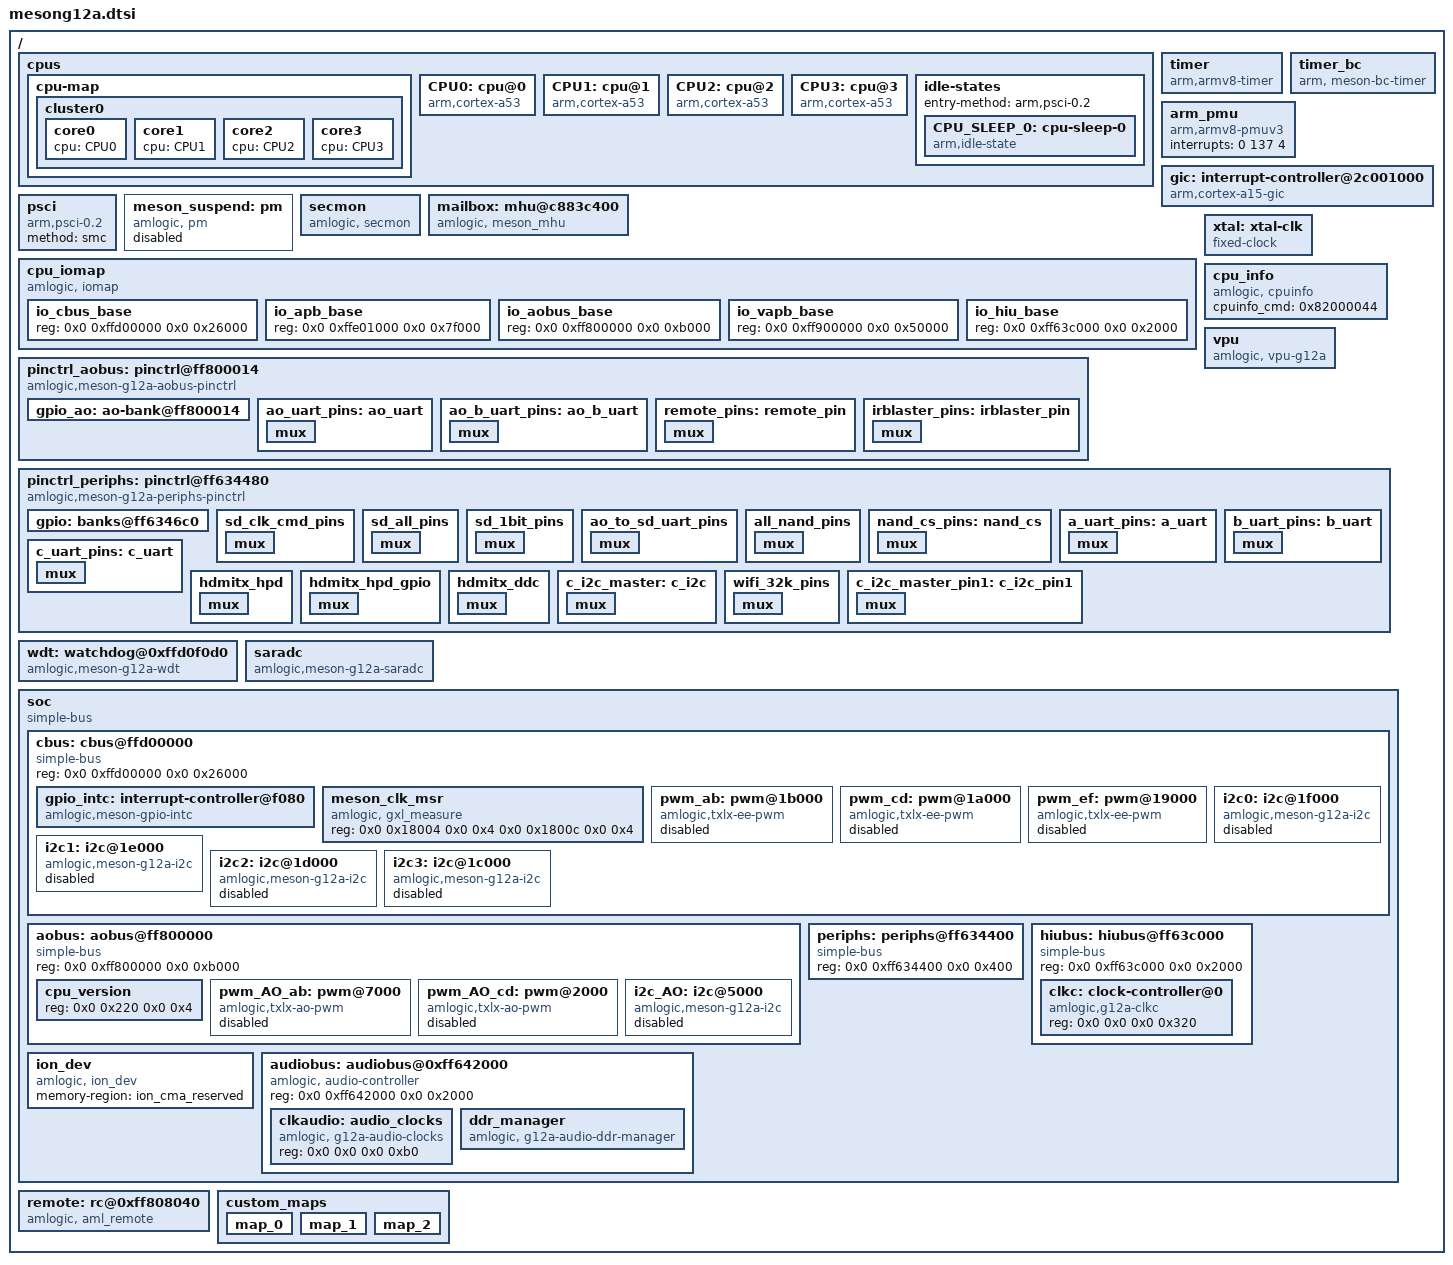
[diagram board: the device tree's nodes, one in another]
/*
 * arch/arm64/boot/dts/amlogic/mesong12a.dtsi
 *
 * Copyright (C) 2017 Amlogic, Inc. All rights reserved.
 *
 * This program is free software; you can redistribute it and/or modify
 * it under the terms of the GNU General Public License as published by
 * the Free Software Foundation; either version 2 of the License, or
 * (at your option) any later version.
 *
 * This program is distributed in the hope that it will be useful, but WITHOUT
 * ANY WARRANTY; without even the implied warranty of MERCHANTABILITY or
 * FITNESS FOR A PARTICULAR PURPOSE.  See the GNU General Public License for
 * more details.
 *
 */

#include <dt-bindings/interrupt-controller/arm-gic.h>
#include <dt-bindings/clock/amlogic,g12a-clkc.h>
#include <dt-bindings/clock/amlogic,g12a-audio-clk.h>
#include <dt-bindings/iio/adc/amlogic-saradc.h>
#include <dt-bindings/gpio/meson-g12a-gpio.h>
#include <dt-bindings/pwm/pwm.h>
#include <dt-bindings/pwm/meson.h>
#include <dt-bindings/i2c/i2c-meson.h>
#include <dt-bindings/gpio/gpio.h>
#include <dt-bindings/input/input.h>
#include <dt-bindings/input/meson_rc.h>
#include <dt-bindings/phy/phy-amlogic-pcie.h>
#include "mesong12a-dvalin.dtsi"

/ {
	cpus:cpus {
		#address-cells = <2>;
		#size-cells = <0>;

		cpu-map {
			cluster0:cluster0 {
				core0 {
					cpu = <&CPU0>;
				};
				core1 {
					cpu = <&CPU1>;
				};
				core2 {
					cpu = <&CPU2>;
				};
				core3 {
					cpu = <&CPU3>;
				};
			};
		};

		CPU0:cpu@0 {
			device_type = "cpu";
			compatible = "arm,cortex-a53","arm,armv8";
			reg = <0x0 0x0>;
			enable-method = "psci";
			//clocks = <&scpi_dvfs 0>;
			//clock-names = "cpu-cluster.0";
			//cpu-idle-states = <&CPU_SLEEP_0>;
		};

		CPU1:cpu@1 {
			device_type = "cpu";
			compatible = "arm,cortex-a53","arm,armv8";
			reg = <0x0 0x1>;
			enable-method = "psci";
			//clocks = <&scpi_dvfs 0>;
			//clock-names = "cpu-cluster.0";
			//cpu-idle-states = <&CPU_SLEEP_0>;
		};

		CPU2:cpu@2 {
			device_type = "cpu";
			compatible = "arm,cortex-a53","arm,armv8";
			reg = <0x0 0x2>;
			enable-method = "psci";
			//clocks = <&scpi_dvfs 0>;
			//clock-names = "cpu-cluster.0";
			//cpu-idle-states = <&CPU_SLEEP_0>;
		};

		CPU3:cpu@3 {
			device_type = "cpu";
			compatible = "arm,cortex-a53","arm,armv8";
			reg = <0x0 0x3>;
			enable-method = "psci";
			//clocks = <&scpi_dvfs 0>;
			//clock-names = "cpu-cluster.0";
			//cpu-idle-states = <&CPU_SLEEP_0>;
		};

		idle-states {
			entry-method = "arm,psci-0.2";
			CPU_SLEEP_0: cpu-sleep-0 {
					compatible = "arm,idle-state";
					arm,psci-suspend-param = <0x0010000>;
					local-timer-stop;
					entry-latency-us = <5000>;
					exit-latency-us = <5000>;
					min-residency-us = <15000>;
			};
		};
	};

	timer {
		compatible = "arm,armv8-timer";
		interrupts = <GIC_PPI 13 0xff08>,
				<GIC_PPI 14 0xff08>,
				<GIC_PPI 11 0xff08>,
				<GIC_PPI 10 0xff08>;
	};

	timer_bc {
		compatible = "arm, meson-bc-timer";
		reg=   <0x0 0xffd0f190 0x0 0x4 0x0 0xffd0f194 0x0 0x4>;
		timer_name = "Meson TimerF";
		clockevent-rating=<300>;
		clockevent-shift=<20>;
		clockevent-features=<0x23>;
		interrupts = <0 60 1>;
		bit_enable=<16>;
		bit_mode=<12>;
		bit_resolution=<0>;
	};
	arm_pmu {
		compatible = "arm,armv8-pmuv3";
		interrupts = <0 137 4>;
	};

	gic: interrupt-controller@2c001000 {
		compatible = "arm,cortex-a15-gic", "arm,cortex-a9-gic";
		#interrupt-cells = <3>;
		#address-cells = <0>;
		interrupt-controller;
		reg = <0x0 0xffc01000 0 0x1000>,
		      <0x0 0xffc02000 0 0x0100>;
		interrupts = <GIC_PPI 9 0xf04>;
	};

	psci {
		compatible = "arm,psci-0.2";
		method = "smc";
	};

	meson_suspend:pm {
		compatible = "amlogic, pm";
		status = "disabled";
		device_name = "aml_pm";
		reg = <0x0 0xff80023c 0x0 0x4>;
	};

	secmon {
		compatible = "amlogic, secmon";
		memory-region = <&secmon_reserved>;
		in_base_func = <0x82000020>;
		out_base_func = <0x82000021>;
		reserve_mem_size = <0x00300000>;
	};

	mailbox: mhu@c883c400 {
		compatible = "amlogic, meson_mhu";
		reg = <0x0 0xff63c400 0x0 0x4c>,   /* MHU registers */
		      <0x0 0xfffd3000 0x0 0x800>;   /* Payload area */
		interrupts = <0 209 1>,   /* low priority interrupt */
			     <0 210 1>;   /* high priority interrupt */
		#mbox-cells = <1>;
		mbox-names = "cpu_to_scp_low", "cpu_to_scp_high";
		mboxes = <&mailbox 0 &mailbox 1>;
	};

	cpu_iomap {
		compatible = "amlogic, iomap";
		#address-cells=<2>;
		#size-cells=<2>;
		ranges;
		io_cbus_base {
			reg = <0x0 0xffd00000 0x0 0x26000>;
		};
		io_apb_base {
			reg = <0x0 0xffe01000 0x0 0x7f000>;
		};
		io_aobus_base {
			reg = <0x0 0xff800000 0x0 0xb000>;
		};
		io_vapb_base {
			reg = <0x0 0xff900000 0x0 0x50000>;
		};
		io_hiu_base {
			reg = <0x0 0xff63c000 0x0 0x2000>;
		};
	};

	xtal: xtal-clk {
		compatible = "fixed-clock";
		clock-frequency = <24000000>;
		clock-output-names = "xtal";
		#clock-cells = <0>;
	};

	cpu_info {
		compatible = "amlogic, cpuinfo";
		status = "okay";
		cpuinfo_cmd = <0x82000044>;
	};

	vpu {
		compatible = "amlogic, vpu-g12a";
		dev_name = "vpu";
		status = "okay";
		clocks = <&clkc CLKID_VAPB_MUX>,
			<&clkc CLKID_VPU_INTR>,
			<&clkc CLKID_VPU_P0_COMP>,
			<&clkc CLKID_VPU_P1_COMP>,
			<&clkc CLKID_VPU_MUX>;
		clock-names = "vapb_clk",
			"vpu_intr_gate",
			"vpu_clk0",
			"vpu_clk1",
			"vpu_clk";
		clk_level = <7>;
		/* 0: 100.0M    1: 166.7M    2: 200.0M    3: 250.0M */
		/* 4: 333.3M    5: 400.0M    6: 500.0M    7: 666.7M */
	};

	pinctrl_aobus: pinctrl@ff800014{
		compatible = "amlogic,meson-g12a-aobus-pinctrl";
		#address-cells = <2>;
		#size-cells = <2>;
		ranges;

		gpio_ao: ao-bank@ff800014{
			reg = <0x0 0xff800014 0x0 0x8>,
				  <0x0 0xff800024 0x0 0x14>,
				  <0x0 0xff80001c 0x0 0x8>;
			reg-names = "mux","gpio", "drive-strength";
			gpio-controller;
			#gpio-cells = <2>;
		};
	};

	pinctrl_periphs: pinctrl@ff634480{
		compatible = "amlogic,meson-g12a-periphs-pinctrl";
		#address-cells = <2>;
		#size-cells = <2>;
		ranges;

		gpio: banks@ff6346c0{
			reg = <0x0 0xff6346c0 0x0 0x40>,
				  <0x0 0xff6344e8 0x0 0x18>,
				  <0x0 0xff634520 0x0 0x18>,
				  <0x0 0xff634440 0x0 0x4c>,
				  <0x0 0xff634740 0x0 0x1c>;
			reg-names = "mux",
				"pull",
				"pull-enable",
				"gpio",
				"drive-strength";
			gpio-controller;
			#gpio-cells = <2>;
		};
	};

	wdt: watchdog@0xffd0f0d0 {
		compatible = "amlogic,meson-g12a-wdt";
		status = "okay";
		reg = <0x0 0xffd0f0d0 0x0 0x10>;
		clock-names = "xtal";
		clocks = <&xtal>;
	};

	saradc:saradc {
		compatible = "amlogic,meson-g12a-saradc";
		status = "okay";
		#io-channel-cells = <1>;
		clocks = <&xtal>, <&clkc CLKID_SARADC_GATE>;
		clock-names = "xtal", "saradc_clk";
		interrupts = <GIC_SPI 200 IRQ_TYPE_EDGE_RISING>;
		reg = <0x0 0xff809000 0x0 0x48>;
	};

	soc {
		compatible = "simple-bus";
		#address-cells = <2>;
		#size-cells = <2>;
		ranges;

		cbus: cbus@ffd00000 {
			compatible = "simple-bus";
			reg = <0x0 0xffd00000 0x0 0x26000>;
			#address-cells = <2>;
			#size-cells = <2>;
			ranges = <0x0 0x0 0x0 0xffd00000 0x0 0x26000>;

			gpio_intc: interrupt-controller@f080 {
				compatible = "amlogic,meson-gpio-intc",
						"amlogic,meson-g12a-gpio-intc";
				reg = <0x0 0xf080 0x0 0x10>;
				interrupt-controller;
				#interrupt-cells = <2>;
				amlogic,channel-interrupts =
						<64 65 66 67 68 69 70 71>;
				status = "okay";
			};

			meson_clk_msr {
				compatible = "amlogic, gxl_measure";
				reg = <0x0 0x18004 0x0 0x4
		       0x0 0x1800c 0x0 0x4>;
			};

			pwm_ab: pwm@1b000 {
				compatible = "amlogic,txlx-ee-pwm";
				reg = <0x0 0x1b000 0x0 0x20>;
				#pwm-cells = <3>;
				clocks = <&xtal>,
						<&xtal>,
						<&xtal>,
						<&xtal>;
				clock-names = "clkin0",
						"clkin1",
						"clkin2",
						"clkin3";
				/* default xtal 24m  clkin0-clkin2 and
				 * clkin1-clkin3 should be set the same
				 */
				status = "disabled";
			};

			pwm_cd: pwm@1a000 {
				compatible = "amlogic,txlx-ee-pwm";
				reg = <0x0 0x1a000  0x0 0x20>;
				#pwm-cells = <3>;
				clocks = <&xtal>,
						<&xtal>,
						<&xtal>,
						<&xtal>;
				clock-names = "clkin0",
						"clkin1",
						"clkin2",
						"clkin3";
				status = "disabled";
			};

			pwm_ef: pwm@19000 {
				compatible = "amlogic,txlx-ee-pwm";
				reg = <0x0 0x19000  0x0 0x20>;
				#pwm-cells = <3>;
				clocks = <&xtal>,
						<&xtal>,
						<&xtal>,
						<&xtal>;
				clock-names = "clkin0",
						"clkin1",
						"clkin2",
						"clkin3";
				status = "disabled";
			};

			i2c0: i2c@1f000 {
				compatible = "amlogic,meson-g12a-i2c";
				status = "disabled";
				reg = <0x0 0x1f000 0x0 0x20>;
				interrupts = <GIC_SPI 21 IRQ_TYPE_EDGE_RISING>,
					<GIC_SPI 47 IRQ_TYPE_EDGE_RISING>;
				#address-cells = <1>;
				#size-cells = <0>;
				clocks = <&clkc CLKID_I2C>;
				clock-names = "clk_i2c";
				dev-id = <MESON_I2C_MASTER0>;
			};

			i2c1: i2c@1e000 {
				compatible = "amlogic,meson-g12a-i2c";
				status = "disabled";
				reg = <0x0 0x1e000 0x0 0x20>;
				interrupts = <GIC_SPI 214 IRQ_TYPE_EDGE_RISING>,
					<GIC_SPI 48 IRQ_TYPE_EDGE_RISING>;
				#address-cells = <1>;
				#size-cells = <0>;
				clocks = <&clkc CLKID_I2C>;
				clock-names = "clk_i2c";
				dev-id = <MESON_I2C_MASTER1>;
			};

			i2c2: i2c@1d000 {
				compatible = "amlogic,meson-g12a-i2c";
				status = "disabled";
				reg = <0x0 0x1d000 0x0 0x20>;
				interrupts = <GIC_SPI 215 IRQ_TYPE_EDGE_RISING>,
					<GIC_SPI 49 IRQ_TYPE_EDGE_RISING>;
				#address-cells = <1>;
				#size-cells = <0>;
				clocks = <&clkc CLKID_I2C>;
				clock-names = "clk_i2c";
				dev-id = <MESON_I2C_MASTER2>;
			};

			i2c3: i2c@1c000 {
				compatible = "amlogic,meson-g12a-i2c";
				status = "disabled";
				reg = <0x0 0x1c000 0x0 0x20>;
				interrupts = <GIC_SPI 39 IRQ_TYPE_EDGE_RISING>,
					<GIC_SPI 50 IRQ_TYPE_EDGE_RISING>;
				#address-cells = <1>;
				#size-cells = <0>;
				clocks = <&clkc CLKID_I2C>;
				clock-names = "clk_i2c";
				dev-id = <MESON_I2C_MASTER3>;
			};

		}; /* end of cbus */

		aobus: aobus@ff800000 {
			compatible = "simple-bus";
			reg = <0x0 0xff800000 0x0 0xb000>;
			#address-cells = <2>;
			#size-cells = <2>;
			ranges = <0x0 0x0 0x0 0xff800000 0x0 0xb000>;

			cpu_version {
				reg=<0x0 0x220 0x0 0x4>;
			};

			pwm_AO_ab: pwm@7000 {
				compatible = "amlogic,txlx-ao-pwm";
				reg = <0x0 0x7000  0x0 0x20>;
				#pwm-cells = <3>;
				clocks = <&xtal>,
					 <&xtal>,
					 <&xtal>,
					 <&xtal>;
				clock-names = "clkin0",
					      "clkin1",
					      "clkin2",
					      "clkin3";
				status = "disabled";
			};

			pwm_AO_cd: pwm@2000 {
				compatible = "amlogic,txlx-ao-pwm";
				reg = <0x0 0x2000  0x0 0x20>;
				#pwm-cells = <3>;
				clocks = <&xtal>,
					 <&xtal>,
					 <&xtal>,
					 <&xtal>;
				clock-names = "clkin0",
					      "clkin1",
					      "clkin2",
					      "clkin3";
				status = "disabled";
			};

			i2c_AO: i2c@5000 {
				compatible = "amlogic,meson-g12a-i2c";
				status = "disabled";
				reg = <0x0 0x05000 0x0 0x20>;
				interrupts = <GIC_SPI 195 IRQ_TYPE_EDGE_RISING>;
				#address-cells = <1>;
				#size-cells = <0>;
				clocks = <&clkc CLKID_I2C>;
				clock-names = "clk_i2c";
				dev-id = <MESON_I2C_MASTERAO>;
			};

		};/* end of aobus */

		periphs: periphs@ff634400 {
			compatible = "simple-bus";
			reg = <0x0 0xff634400 0x0 0x400>;
			#address-cells = <2>;
			#size-cells = <2>;
			ranges = <0x0 0x0 0x0 0xff634400 0x0 0x400>;

		};/* end of periphs */

		hiubus: hiubus@ff63c000 {
			compatible = "simple-bus";
			reg = <0x0 0xff63c000 0x0 0x2000>;
			#address-cells = <2>;
			#size-cells = <2>;
			ranges = <0x0 0x0 0x0 0xff63c000 0x0 0x2000>;

			clkc: clock-controller@0 {
				compatible = "amlogic,g12a-clkc";
				#clock-cells = <1>;
				reg = <0x0 0x0 0x0 0x320>;
			};
		};/* end of hiubus*/

		ion_dev {
			compatible = "amlogic, ion_dev";
			memory-region = <&ion_cma_reserved>;
		};/* end of ion_dev*/

		audiobus: audiobus@0xff642000 {
			compatible = "amlogic, audio-controller", "simple-bus";
			reg = <0x0 0xff642000 0x0 0x2000>;
			#address-cells = <2>;
			#size-cells = <2>;
			ranges = <0x0 0x0 0x0 0xff642000 0x0 0x2000>;
			clkaudio: audio_clocks {
				compatible = "amlogic, g12a-audio-clocks";
				#clock-cells = <1>;
				reg = <0x0 0x0 0x0 0xb0>;
			};
			ddr_manager {
				compatible = "amlogic, g12a-audio-ddr-manager";
				interrupts = <
					GIC_SPI 148 IRQ_TYPE_EDGE_RISING
					GIC_SPI 149 IRQ_TYPE_EDGE_RISING
					GIC_SPI 150 IRQ_TYPE_EDGE_RISING
					GIC_SPI 152 IRQ_TYPE_EDGE_RISING
					GIC_SPI 153 IRQ_TYPE_EDGE_RISING
					GIC_SPI 154 IRQ_TYPE_EDGE_RISING
				>;
				interrupt-names =
					"toddr_a", "toddr_b", "toddr_c",
					"frddr_a", "frddr_b", "frddr_c";
			};
		};/* end of audiobus*/

	}; /* end of soc*/

	remote:rc@0xff808040 {
		compatible = "amlogic, aml_remote";
		dev_name = "meson-remote";
		reg = <0x0 0xff808040 0x00 0x44>, /*Multi-format IR controller*/
			<0x0 0xff808000 0x00 0x20>; /*Legacy IR controller*/
		status = "okay";
		protocol = <REMOTE_TYPE_NEC>;
		interrupts = <0 196 1>;
		pinctrl-names = "default";
		pinctrl-0 = <&remote_pins>;
		map = <&custom_maps>;
		max_frame_time = <200>; /*set software decoder max frame time*/
	};

	custom_maps:custom_maps {
		mapnum = <3>;
		map0 = <&map_0>;
		map1 = <&map_1>;
		map2 = <&map_2>;
		map_0: map_0{
			mapname = "amlogic-remote-1";
			customcode = <0xfb04>;
			release_delay = <80>;
			size  = <50>;   /*keymap size*/
			keymap = <REMOTE_KEY(0x47, KEY_0)
				REMOTE_KEY(0x13, KEY_1)
				REMOTE_KEY(0x10, KEY_2)
				REMOTE_KEY(0x11, KEY_3)
				REMOTE_KEY(0x0F, KEY_4)
				REMOTE_KEY(0x0C, KEY_5)
				REMOTE_KEY(0x0D, KEY_6)
				REMOTE_KEY(0x0B, KEY_7)
				REMOTE_KEY(0x08, KEY_8)
				REMOTE_KEY(0x09, KEY_9)
				REMOTE_KEY(0x5C, KEY_RIGHTCTRL)
				REMOTE_KEY(0x51, KEY_F3)
				REMOTE_KEY(0x50, KEY_F4)
				REMOTE_KEY(0x40, KEY_F5)
				REMOTE_KEY(0x4d, KEY_F6)
				REMOTE_KEY(0x43, KEY_F7)
				REMOTE_KEY(0x17, KEY_F8)
				REMOTE_KEY(0x00, KEY_F9)
				REMOTE_KEY(0x01, KEY_F10)
				REMOTE_KEY(0x16, KEY_F11)
				REMOTE_KEY(0x49, KEY_BACKSPACE)
				REMOTE_KEY(0x06, KEY_PROPS)
				REMOTE_KEY(0x14, KEY_UNDO)
				REMOTE_KEY(0x44, KEY_UP)
				REMOTE_KEY(0x1D, KEY_DOWN)
				REMOTE_KEY(0x1C, KEY_LEFT)
				REMOTE_KEY(0x48, KEY_RIGHT)
				REMOTE_KEY(0x53, KEY_LEFTMETA)
				REMOTE_KEY(0x45, KEY_PAGEUP)
				REMOTE_KEY(0x19, KEY_PAGEDOWN)
				REMOTE_KEY(0x52, KEY_PAUSE)
				REMOTE_KEY(0x05, KEY_HANGEUL)
				REMOTE_KEY(0x59, KEY_HANJA)
				REMOTE_KEY(0x1b, KEY_SCALE)
				REMOTE_KEY(0x04, KEY_KPCOMMA)
				REMOTE_KEY(0x1A, KEY_POWER)
				REMOTE_KEY(0x0A, KEY_TAB)
				REMOTE_KEY(0x0e, KEY_MUTE)
				REMOTE_KEY(0x1F, KEY_HOME)
				REMOTE_KEY(0x1e, KEY_FRONT)
				REMOTE_KEY(0x07, KEY_COPY)
				REMOTE_KEY(0x12, KEY_OPEN)
				REMOTE_KEY(0x54, KEY_PASTE)
				REMOTE_KEY(0x02, KEY_FIND)
				REMOTE_KEY(0x4f, KEY_A)
				REMOTE_KEY(0x42, KEY_B)
				REMOTE_KEY(0x5d, KEY_C)
				REMOTE_KEY(0x4c, KEY_D)
				REMOTE_KEY(0x58, KEY_CUT)
				REMOTE_KEY(0x55, KEY_CALC)>;
		};
		map_1: map_1{
			mapname = "amlogic-remote-2";
			customcode = <0xfe01>;
			release_delay = <80>;
			size  = <53>;
			keymap = <REMOTE_KEY(0x01, KEY_1)
				REMOTE_KEY(0x02, KEY_2)
				REMOTE_KEY(0x03, KEY_3)
				REMOTE_KEY(0x04, KEY_4)
				REMOTE_KEY(0x05, KEY_5)
				REMOTE_KEY(0x06, KEY_6)
				REMOTE_KEY(0x07, KEY_7)
				REMOTE_KEY(0x08, KEY_8)
				REMOTE_KEY(0x09, KEY_9)
				REMOTE_KEY(0x0a, KEY_0)
				REMOTE_KEY(0x1F, KEY_FN_F1)
				REMOTE_KEY(0x15, KEY_MENU)
				REMOTE_KEY(0x16, KEY_TAB)
				REMOTE_KEY(0x0c, KEY_CHANNELUP)
				REMOTE_KEY(0x0d, KEY_CHANNELDOWN)
				REMOTE_KEY(0x0e, KEY_VOLUMEUP)
				REMOTE_KEY(0x0f, KEY_VOLUMEDOWN)
				REMOTE_KEY(0x11, KEY_HOME)
				REMOTE_KEY(0x1c, KEY_RIGHT)
				REMOTE_KEY(0x1b, KEY_LEFT)
				REMOTE_KEY(0x19, KEY_UP)
				REMOTE_KEY(0x1a, KEY_DOWN)
				REMOTE_KEY(0x1d, KEY_ENTER)
				REMOTE_KEY(0x17, KEY_MUTE)
				REMOTE_KEY(0x49, KEY_FINANCE)
				REMOTE_KEY(0x43, KEY_BACK)
				REMOTE_KEY(0x12, KEY_FN_F4)
				REMOTE_KEY(0x14, KEY_FN_F5)
				REMOTE_KEY(0x18, KEY_FN_F6)
				REMOTE_KEY(0x59, KEY_INFO)
				REMOTE_KEY(0x5a, KEY_STOPCD)
				REMOTE_KEY(0x10, KEY_POWER)
				REMOTE_KEY(0x42, KEY_PREVIOUSSONG)
				REMOTE_KEY(0x44, KEY_NEXTSONG)
				REMOTE_KEY(0x1e, KEY_REWIND)
				REMOTE_KEY(0x4b, KEY_FASTFORWARD)
				REMOTE_KEY(0x58, KEY_PLAYPAUSE)
				REMOTE_KEY(0x46, KEY_PROPS)
				REMOTE_KEY(0x40, KEY_UNDO)
				REMOTE_KEY(0x38, KEY_SCROLLLOCK)
				REMOTE_KEY(0x57, KEY_FN)
				REMOTE_KEY(0x5b, KEY_FN_ESC)
				REMOTE_KEY(0x54, KEY_RED)
				REMOTE_KEY(0x4c, KEY_GREEN)
				REMOTE_KEY(0x4e, KEY_YELLOW)
				REMOTE_KEY(0x55, KEY_BLUE)
				REMOTE_KEY(0x53, KEY_BLUETOOTH)
				REMOTE_KEY(0x52, KEY_WLAN)
				REMOTE_KEY(0x39, KEY_CAMERA)
				REMOTE_KEY(0x41, KEY_SOUND)
				REMOTE_KEY(0x0b, KEY_QUESTION)
				REMOTE_KEY(0x00, KEY_CHAT)
				REMOTE_KEY(0x13, KEY_SEARCH)>;
		};
		map_2: map_2{
			mapname = "amlogic-remote-3";
			customcode = <0xbd02>;
			release_delay = <80>;
			size  = <17>;
			keymap = <REMOTE_KEY(0xca,103)
			REMOTE_KEY(0xd2,108)
			REMOTE_KEY(0x99,105)
			REMOTE_KEY(0xc1,106)
			REMOTE_KEY(0xce,97)
			REMOTE_KEY(0x45,116)
			REMOTE_KEY(0xc5,133)
			REMOTE_KEY(0x80,113)
			REMOTE_KEY(0xd0,15)
			REMOTE_KEY(0xd6,125)
			REMOTE_KEY(0x95,102)
			REMOTE_KEY(0xdd,104)
			REMOTE_KEY(0x8c,109)
			REMOTE_KEY(0x89,131)
			REMOTE_KEY(0x9c,130)
			REMOTE_KEY(0x9a,120)
			REMOTE_KEY(0xcd,121)>;
		};
	};

};/* end of / */

&pinctrl_aobus {
	ao_uart_pins:ao_uart {
		mux {
			groups = "uart_ao_tx_a",
				"uart_ao_rx_a";
			function = "uart_ao_a";
		};
	};

	ao_b_uart_pins:ao_b_uart {
		mux {
			groups = "uart_ao_tx_b_2",
				"uart_ao_rx_b_3";
			function = "uart_ao_b";
		};
	};
};

&pinctrl_periphs {
	/* sdemmc portB */
	sd_clk_cmd_pins:sd_clk_cmd_pins {
		mux {
			groups = "sdcard_cmd_c",
				   "sdcard_clk_c";
			function = "sdcard";
			input-enable;
			bias-pull-up;
		};
	};

	sd_all_pins:sd_all_pins {
		mux {
			groups = "sdcard_d0_c",
				   "sdcard_d1_c",
				   "sdcard_d2_c",
				   "sdcard_d3_c",
				   "sdcard_cmd_c",
				   "sdcard_clk_c";
			function = "sdcard";
			input-enable;
			bias-pull-up;
		};
	};
	sd_1bit_pins:sd_1bit_pins {
		mux {
			groups = "sdcard_d0_c",
					"sdcard_cmd_c",
					"sdcard_clk_c";
			function = "sdcard";
			input-enable;
			bias-pull-up;
		};
	};

	ao_to_sd_uart_pins:ao_to_sd_uart_pins {
		mux {
			groups = "uart_tx_ao_a_c4",
					"uart_rx_ao_a_c5";
			function = "uart_ao_a_ee";
			bias-pull-up;
			input-enable;
		};
	};

	all_nand_pins: all_nand_pins {
		mux {
			groups =  "emmc_nand_d0",
				"emmc_nand_d1",
				"emmc_nand_d2",
				"emmc_nand_d3",
				"emmc_nand_d4",
				"emmc_nand_d5",
				"emmc_nand_d6",
				"emmc_nand_d7",
				"nand_ce0",
				"nand_ale",
				"nand_cle",
				"nand_wen_clk",
				"nand_ren_wr",
				"nand_rb0";
			function = "nand";
			input-enable;
		};
	};

	nand_cs_pins: nand_cs {
		mux {
			groups = "nand_ce0";
			function = "nand";
		};
	};

	a_uart_pins:a_uart {
		mux {
			groups = "uart_tx_a",
				"uart_rx_a",
				"uart_cts_a",
				"uart_rts_a";
			function = "uart_a";
		};
	};

	b_uart_pins:b_uart {
		mux {
			groups = "uart_tx_b",
				"uart_rx_b";
			function = "uart_b";
		};
	};

	c_uart_pins:c_uart {
		mux {
			groups = "uart_tx_c",
				"uart_rx_c";
			function = "uart_c";
		};
	};

	hdmitx_hpd: hdmitx_hpd {
		mux {
			groups = "hdmitx_hpd_in";
			function = "hdmitx";
			bias-disable;
		};
	};

	hdmitx_hpd_gpio: hdmitx_hpd_gpio {
		mux {
			groups = "GPIOH_1";
			function = "gpio_periphs";
			bias-disable;
		};
	};

	hdmitx_ddc: hdmitx_ddc {
		mux {
			groups = "hdmitx_sda",
				"hdmitx_sck";
			function = "hdmitx";
			bias-disable;
		};
	};

	c_i2c_master: c_i2c {
		mux {
			groups = "i2c0_sda_c",
			"i2c0_sck_c";
			function = "i2c3";
			bias-disable;
		};
	};

	wifi_32k_pins:wifi_32k_pins {
		mux {
			groups = "pwm_e";
			function = "pwm_e";
		};
	};

	c_i2c_master_pin1:c_i2c_pin1 {
		mux {
			groups = "i2c3_sck_a",
				"i2c3_sda_a";
			function = "i2c3";
		};
	};
};

&pinctrl_aobus {
	remote_pins:remote_pin {
		mux {
			groups = "remote_input_ao";
			function = "remote_input_ao";
		};
	};

	irblaster_pins:irblaster_pin {
		mux {
			groups = "remote_out_ao";
			function = "remote_out_ao";
		};
	};
}; /* end of pinctrl_aobus */
